AUTOSAR XML (schema 00048)
package /Eps_Repository/ActiveReturn/ActiveReturnCheck
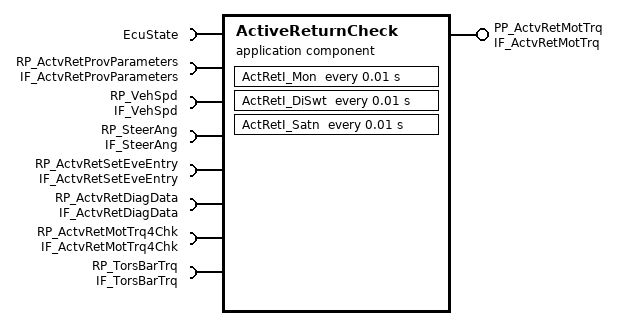
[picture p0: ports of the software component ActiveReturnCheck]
  application sw component type ActiveReturnCheck
    8 x require port:
      EcuState: required-interface=EcuState
      RP_ActvRetProvParameters: required-com-specs=[Get_ActvRetMaxMotTrqDepOnSteerAng, Get_ActvRetMaxMotTrqDepOnVehSpd, Get_ActvRetMaxTBT4ShtDwn], required-interface=IF_ActvRetProvParameters
      RP_VehSpd: required-com-specs=[{data-element=AbsMaxSafeVehSpd, init-value=0}, {data-element=AbsAvgVehSpd, init-value=0}], required-interface=IF_VehSpd
      RP_SteerAng: required-com-specs=[{data-element=SteerAng, init-value=0}, {data-element=SteerAngSt, init-value=0}], required-interface=IF_SteerAng
      RP_ActvRetSetEveEntry: client-com-spec=Set_ActvRetEntry, required-interface=IF_ActvRetSetEveEntry
      RP_ActvRetDiagData: client-com-spec=Set_ActvRetDiagData, required-interface=IF_ActvRetDiagData
      RP_ActvRetMotTrq4Chk: nonqueued-receiver-com-spec{data-element=ActvRetMotTrq4Chk, init-value=0}, required-interface=IF_ActvRetMotTrq4Chk
      RP_TorsBarTrq: nonqueued-receiver-com-spec{data-element=TorsBarTrq, init-value=0}, required-interface=IF_TorsBarTrq
    provide port PP_ActvRetMotTrq: nonqueued-sender-com-spec{data-element=ActvRetMotTrq, init-value=0}, provided-interface=IF_ActvRetMotTrq
    behavior IB_ActiveReturnCheck: data-type-mapping=[DTMS_ActvRetCdp, DTMS_ActvRetChk, DTMS_ActvRet_L_Adpr, DTMS_ActvRet], handle-termination-and-restart=NO-SUPPORT
      ar-typed-per-instance-memorys:
        data PIM_ActvRetDi: sw-calibration-access=READ-ONLY, type=ADT_ActvRetDi, init-value=0
      timing event TE_ActiveReturnCheck_Mon: start-on-event=ActRetI_Mon, period=0.01
        disabled-mode:
          EcuState.ApplicationModes.EcuInit
          EcuState.ApplicationModes.ApplicationInit
          EcuState.ApplicationModes.PostRun
          EcuState.ApplicationModes.Error
          EcuState.ApplicationModes.ApplicationOff
      timing event TE_ActiveReturnCheck_DiSwt: start-on-event=ActRetI_DiSwt, period=0.01
        disabled-mode:
          EcuState.ApplicationModes.EcuInit
          EcuState.ApplicationModes.ApplicationInit
          EcuState.ApplicationModes.PostRun
          EcuState.ApplicationModes.Error
          EcuState.ApplicationModes.ApplicationOff
      timing event TE_ActiveReturnCheck_Satn: start-on-event=ActRetI_Satn, period=0.01
        disabled-mode:
          EcuState.ApplicationModes.EcuInit
          EcuState.ApplicationModes.ApplicationInit
          EcuState.ApplicationModes.PostRun
          EcuState.ApplicationModes.Error
          EcuState.ApplicationModes.ApplicationOff
      explicit-inter-runnable-variables:
        6 x data, all with sw-calibration-access=READ-ONLY, init-value=0:
          IRV_ActvRetMotTrqSatn: type=ADT_ActvRetMotTrqSatn
          IRV_ActvRetDi: type=ADT_ActvRetDi
          IRV_ActvRetMaxMotTrqMin: type=ADT_ActvRetMaxMotTrqMin
          IRV_ActvRetAbsTorsBarTrqSat: type=ADT_ActvRetAbsTorsBarTrqSat
          IRV_ActvRetAbsMaxSafeVehSpdSat: type=ADT_ActvRetAbsMaxSafeVehSpdSat
          IRV_ActvRetAbsSteerAngSat: type=ADT_ActvRetAbsSteerAngSat
      runnable ActRetI_Mon: symbol=ActRetI_Monitoring
        data-receive-point-by-arguments:
          access DRP_RP_TorsBarTrq_TorsBarTrq: accessed-variable=RP_TorsBarTrq.TorsBarTrq
          access DRP_RP_VehSpd_AbsMaxSafeVehSpd: accessed-variable=RP_VehSpd.AbsMaxSafeVehSpd
          access DRP_RP_SteerAng_SteerAng: accessed-variable=RP_SteerAng.SteerAng
        read-local-variables:
          5 x access:
            IRVRA_IRV_ActvRetMotTrqSatn: accessed-variable=IRV_ActvRetMotTrqSatn
            IRVRA_IRV_ActvRetAbsTorsBarTrqSat: accessed-variable=IRV_ActvRetAbsTorsBarTrqSat
            IRVRA_IRV_ActvRetMaxMotTrqMin: accessed-variable=IRV_ActvRetMaxMotTrqMin
            IRVRA_IRV_ActvRetAbsMaxSafeVehSpdSat: accessed-variable=IRV_ActvRetAbsMaxSafeVehSpdSat
            IRVRA_IRV_ActvRetAbsSteerAngSat: accessed-variable=IRV_ActvRetAbsSteerAngSat
        5 x sync call, all with timeout=0:
          SSCP_RP_ActvRetProvParameters_Get_ActvRetMaxMotTrqDepOnSteerAng: operation=RP_ActvRetProvParameters.Get_ActvRetMaxMotTrqDepOnSteerAng
          SSCP_RP_ActvRetProvParameters_Get_ActvRetMaxMotTrqDepOnVehSpd: operation=RP_ActvRetProvParameters.Get_ActvRetMaxMotTrqDepOnVehSpd
          SSCP_RP_ActvRetProvParameters_Get_ActvRetMaxTBT4ShtDwn: operation=RP_ActvRetProvParameters.Get_ActvRetMaxTBT4ShtDwn
          SSCP_RP_ActvRetSetEveEntry_ActvRetSet_Entry: operation=RP_ActvRetSetEveEntry.Set_ActvRetEntry
          SSCP_RP_ActvRetDiagData_Set_ActvRetDiagData: operation=RP_ActvRetDiagData.Set_ActvRetDiagData
        written-local-variables:
          access IRVWA_IRV_ActvRetDi: accessed-variable=IRV_ActvRetDi
      runnable ActRetI_DiSwt: symbol=ActRetI_DisableSwitch
        data-send-points:
          access DSP_PP_ActvRetMotTrq_ActvRetMotTrq: accessed-variable=PP_ActvRetMotTrq.ActvRetMotTrq
        read-local-variables:
          access IRVRA_IRV_ActvRetDi: accessed-variable=IRV_ActvRetDi
          access IRVRA_IRV_ActvRetMotTrqSatn: accessed-variable=IRV_ActvRetMotTrqSatn
      runnable ActRetI_Satn: symbol=ActRetI_Saturation
        data-receive-point-by-arguments:
          4 x access:
            DRP_RP_ActvRetMotTrq4Chk_ActvRetMotTrq4Chk: accessed-variable=RP_ActvRetMotTrq4Chk.ActvRetMotTrq4Chk
            DRP_RP_TorsBarTrq_TorsBarTrq: accessed-variable=RP_TorsBarTrq.TorsBarTrq
            DRP_RP_SteerAng_SteerAng: accessed-variable=RP_SteerAng.SteerAng
            DRP_RP_VehSpd_AbsMaxSafeVehSpd: accessed-variable=RP_VehSpd.AbsMaxSafeVehSpd
        sync call SSCP_RP_ActvRetProvParameters_Get_ActvRetMaxMotTrqDepOnSteerAng: operation=RP_ActvRetProvParameters.Get_ActvRetMaxMotTrqDepOnSteerAng, timeout=0
        sync call SSCP_RP_ActvRetProvParameters_Get_ActvRetMaxMotTrqDepOnVehSpd: operation=RP_ActvRetProvParameters.Get_ActvRetMaxMotTrqDepOnVehSpd, timeout=0
        sync call SSCP_RP_ActvRetProvParameters_Get_ActvRetMaxTBT4ShtDwn: operation=RP_ActvRetProvParameters.Get_ActvRetMaxTBT4ShtDwn, timeout=0
        written-local-variables:
          5 x access:
            IRVWA_IRV_ActvRetMotTrqSatn: accessed-variable=IRV_ActvRetMotTrqSatn
            IRVWA_IRV_ActvRetAbsTorsBarTrqSat: accessed-variable=IRV_ActvRetAbsTorsBarTrqSat
            IRVWA_IRV_ActvRetMaxMotTrqMin: accessed-variable=IRV_ActvRetMaxMotTrqMin
            IRVWA_IRV_ActvRetAbsMaxSafeVehSpdSat: accessed-variable=IRV_ActvRetAbsMaxSafeVehSpdSat
            IRVWA_IRV_ActvRetAbsSteerAngSat: accessed-variable=IRV_ActvRetAbsSteerAngSat
package /Eps_Repository/ActiveReturn/ActiveReturnCheck/DataTypeMappingSets
  data type mapping set DTMS_ActvRetChk: mode-request-type-map{implementation-data-type=uint8, mode-group=ApplicationModes}
    data-type-maps:
      application-data-type=ADT_ActvRetDi, implementation-data-type=IDT_ActvRetDi
      application-data-type=ADT_ActvRetMotTrq, implementation-data-type=IDT_ActvRetMotTrq
      application-data-type=ADT_ActvRetMotTrqSatn, implementation-data-type=IDT_ActvRetMotTrqSatn
      application-data-type=ADT_ActvRetMaxMotTrqMin, implementation-data-type=IDT_ActvRetMaxMotTrqMin
      application-data-type=ADT_ActvRetAbsTorsBarTrqSat, implementation-data-type=IDT_ActvRetAbsTorsBarTrqSat
      application-data-type=ADT_ActvRetAbsMaxSafeVehSpdSat, implementation-data-type=IDT_AbsMaxSafeVehSpd
      application-data-type=ADT_ActvRetAbsSteerAngSat, implementation-data-type=IDT_ActvRetAbsSteerAngSat
      application-data-type=ADT_MonStatus, implementation-data-type=IDT_MonStatus
      application-data-type=ADT_MonID, implementation-data-type=IDT_MonID
      application-data-type=ADT_PrestoreData, implementation-data-type=IDT_PrestoreData
package /Eps_Repository/ActiveReturn/ActiveReturnCheck/Interfaces
  mode declaration group ApplicationModes: category=ALPHABETIC_ORDER, initial-mode=EcuInit
    8 x mode:
      ApplicationInit
      ApplicationOff
      EcuInit
      Error
      FailOp
      Normal
      PostRun
      Production
  mode switch interface EcuState
    mode group ApplicationModes: type=ApplicationModes
  sender receiver interface IF_ActvRetMotTrq: invalidation-policy{data-element=ActvRetMotTrq, handle-invalid=KEEP}
    data ActvRetMotTrq: sw-addr-method=DAMOS_RAM_DTA, sw-calibration-access=READ-ONLY, type=ADT_ActvRetMotTrq
package /Eps_Repository/ActiveReturn/ActiveReturnCheck/ApplicationDataTypes
  10 x app type, all with category=VALUE:
    ADT_ActvRetDi: compu-method=CM_ZU0, range phys 0..1, raw 0..1
    ADT_ActvRetMotTrq: compu-method=CM_MMOT, range phys -3..3, raw -3072..3072
    ADT_ActvRetMotTrqSatn: compu-method=CM_MMOT, range phys -3..3, raw -3072..3072
    ADT_ActvRetMaxMotTrqMin: compu-method=CM_MMOT, range phys 0..3, raw 0..3072
    ADT_ActvRetAbsSteerAngSat: compu-method=CM_SA_10, range phys 0..1000, raw 0..10000
    ADT_ActvRetAbsTorsBarTrqSat: compu-method=CM_TBTHIGH, range phys 0..25, raw 0..25600
    ADT_ActvRetAbsMaxSafeVehSpdSat: compu-method=CM_VFZHIGH, data-constr=DC_AbsMaxSafeVehSpd
    ADT_MonStatus
    ADT_MonID
    ADT_PrestoreData
package /Eps_Repository/ActiveReturn/ActiveReturnCheck/ImplementationDataTypes
  9 x impl type, all with category=TYPE_REFERENCE:
    IDT_ActvRetDi: range phys 0..1, raw 0..1, implementation-data-type=boolean, invalid-value=Value:255
    IDT_ActvRetMotTrq: range phys -3..3, raw -3072..3072, implementation-data-type=sint16, invalid-value=Value:32767
    IDT_ActvRetMotTrqSatn: range phys -3..3, raw -3072..3072, implementation-data-type=sint16, invalid-value=Value:32767
    IDT_ActvRetAbsTorsBarTrqSat: range phys 0..25, raw 0..25600, implementation-data-type=uint16
    IDT_ActvRetMaxMotTrqMin: range phys 0..3, raw 0..3072, implementation-data-type=uint16
    IDT_ActvRetAbsSteerAngSat: range phys 0..1000, raw 0..10000, implementation-data-type=uint16
    IDT_MonID: implementation-data-type=uint16
    IDT_MonStatus: implementation-data-type=uint8
    IDT_PrestoreData: implementation-data-type=uint32
package /Eps_Repository/ActiveReturn/ActiveReturnCheck/SWAddrMethod
  sw addr method DAMOS_RAM_DTA: memory-allocation-keyword-policy=ADDR-METHOD-SHORT-NAME, section-initialization-policy=INIT, section-type=VAR
package /Eps_Repository/ActiveReturn/ActiveReturn_L_Adapter/Interfaces
  client server interface IF_ActvRetDiagData
    operation Set_ActvRetDiagData
      4 x arg, all with direction=IN, server-argument-impl-policy=USE-ARGUMENT-TYPE:
        ActvRetMotTrqSatn: type=ADT_ActvRetMotTrqSatn
        ActvRetAbsTorsBarTrqMon: type=ADT_ActvRetAbsTorsBarTrqSat
        ActvRetAbsMaxSafeVehSpdMon: type=ADT_ActvRetAbsMaxSafeVehSpdSat
        ActvRetAbsSteerAngMon: type=ADT_ActvRetAbsSteerAngSat
  client server interface IF_ActvRetSetEveEntry
    operation Set_ActvRetEntry
      arg MonStatus_Val: type=ADT_MonStatus, direction=IN, server-argument-impl-policy=USE-ARGUMENT-TYPE
      arg MonID_Val: type=ADT_MonID, direction=IN, server-argument-impl-policy=USE-ARGUMENT-TYPE
      arg PrestoreData_Val: type=ADT_PrestoreData, direction=IN, server-argument-impl-policy=USE-ARGUMENT-TYPE
